VERSION ""

NS_ :

BS_:

BU_:

BO_ 37 MCU_EW_Code: 8 Vector__XXX
 SG_ MCU_Alarm_Level : 0|8@1+ (1,0) [0|0] "" Vector__XXX
 SG_ MCU_Alarm_Code : 8|16@1+ (1,0) [0|0] "" Vector__XXX

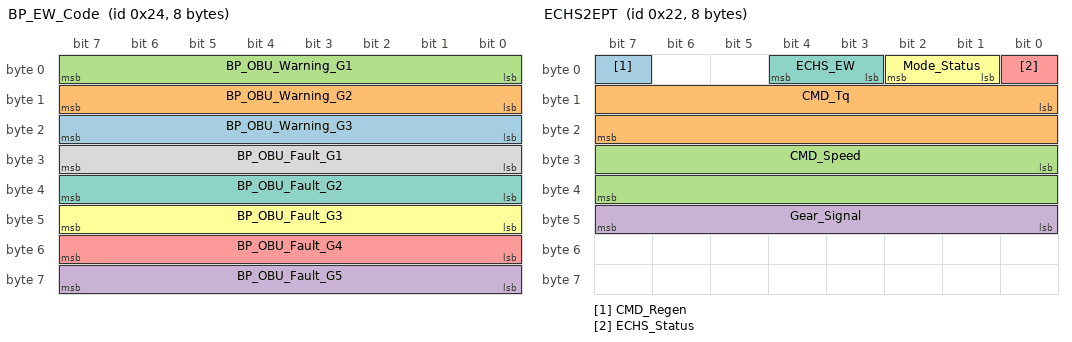
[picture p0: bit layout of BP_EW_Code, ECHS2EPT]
BO_ 36 BP_EW_Code: 8 Vector__XXX
 SG_ BP_OBU_Warning_G3 : 16|8@1+ (1,0) [0|0] "" Vector__XXX
 SG_ BP_OBU_Warning_G2 : 8|8@1+ (1,0) [0|0] "" Vector__XXX
 SG_ BP_OBU_Warning_G1 : 0|8@1+ (1,0) [0|0] "" Vector__XXX
 SG_ BP_OBU_Fault_G5 : 56|8@1+ (1,0) [0|0] "" Vector__XXX
 SG_ BP_OBU_Fault_G4 : 48|8@1+ (1,0) [0|0] "" Vector__XXX
 SG_ BP_OBU_Fault_G3 : 40|8@1+ (1,0) [0|0] "" Vector__XXX
 SG_ BP_OBU_Fault_G2 : 32|8@1+ (1,0) [0|0] "" Vector__XXX
 SG_ BP_OBU_Fault_G1 : 24|8@1+ (1,0) [0|0] "" Vector__XXX

BO_ 34 ECHS2EPT: 8 Vector__XXX
 SG_ CMD_Regen : 7|1@1+ (1,0) [0|0] "" Vector__XXX
 SG_ CMD_Tq : 8|16@1+ (0.1,0) [0|150] "Nm" Vector__XXX
 SG_ CMD_Speed : 24|16@1+ (1,0) [0|6000] "rpm" Vector__XXX
 SG_ Gear_Signal : 40|8@1+ (1,0) [0|0] "" Vector__XXX
 SG_ ECHS_Status : 0|1@1+ (1,0) [0|0] "" Vector__XXX
 SG_ Mode_Status : 1|2@1+ (1,0) [0|0] "" Vector__XXX
 SG_ ECHS_EW : 3|2@1+ (1,0) [0|0] "" Vector__XXX

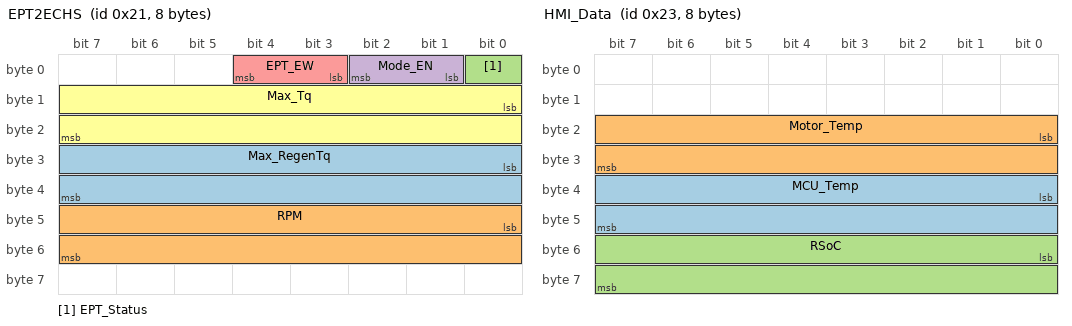
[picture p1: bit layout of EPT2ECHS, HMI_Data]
BO_ 33 EPT2ECHS: 8 Vector__XXX
 SG_ Max_RegenTq : 24|16@1+ (0.1,0) [0|150] "Nm" Vector__XXX
 SG_ RPM : 40|16@1- (1,0) [-15000|15000] "rpm" Vector__XXX
 SG_ EPT_Status : 0|1@1+ (1,0) [0|0] "" Vector__XXX
 SG_ Mode_EN : 1|2@1+ (1,0) [0|0] "" Vector__XXX
 SG_ EPT_EW : 3|2@1+ (1,0) [0|0] "" Vector__XXX
 SG_ Max_Tq : 8|16@1+ (0.1,0) [0|150] "Nm" Vector__XXX

BO_ 35 HMI_Data: 8 Vector__XXX
 SG_ MCU_Temp : 32|16@1- (0.1,-40) [0|100] "¢J" Vector__XXX
 SG_ Motor_Temp : 16|16@1+ (0.1,-40) [0|100] "¢J" Vector__XXX
 SG_ RSoC : 48|16@1+ (0.1,-50) [0|150] "Ah" Vector__XXX
